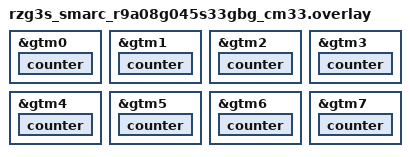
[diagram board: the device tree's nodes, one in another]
/*
 * Copyright (c) 2024 Renesas Electronics Corporation
 *
 * SPDX-License-Identifier: Apache-2.0
 */

&gtm0 {
	status = "okay";

	counter {
		status = "okay";
	};
};

&gtm1 {
	status = "okay";

	counter {
		status = "okay";
	};
};

&gtm2 {
	status = "okay";

	counter {
		status = "okay";
	};
};

&gtm3 {
	status = "okay";

	counter {
		status = "okay";
	};
};

&gtm4 {
	status = "okay";

	counter {
		status = "okay";
	};
};

&gtm5 {
	status = "okay";

	counter {
		status = "okay";
	};
};

&gtm6 {
	status = "okay";

	counter {
		status = "okay";
	};
};

&gtm7 {
	status = "okay";

	counter {
		status = "okay";
	};
};
